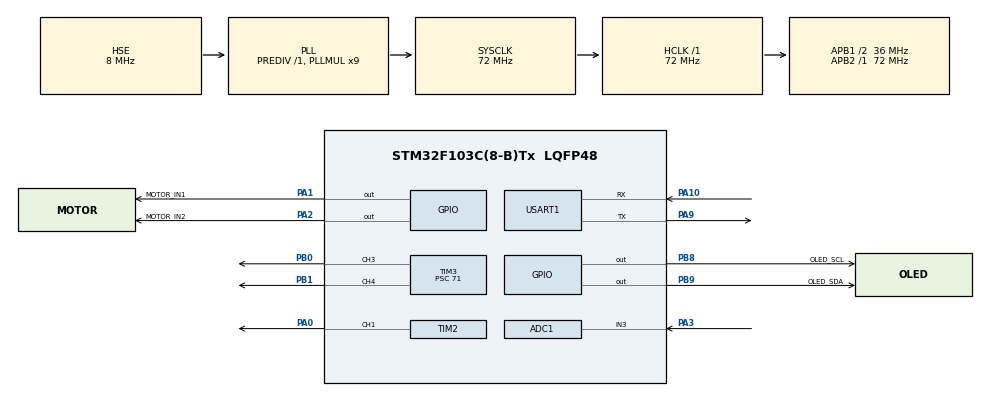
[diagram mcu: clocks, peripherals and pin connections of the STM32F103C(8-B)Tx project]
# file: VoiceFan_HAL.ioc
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ADC1.Channel-0\#ChannelRegularConversion=ADC_CHANNEL_3
ADC1.NbrOfConversionFlag=1
ADC1.Rank-0\#ChannelRegularConversion=1
ADC1.SamplingTime-0\#ChannelRegularConversion=ADC_SAMPLETIME_55CYCLES_5
ADC1.master=1
Mcu.Family=STM32F1
Mcu.Name=STM32F103C(8-B)Tx
Mcu.Package=LQFP48
NVIC.PriorityGroup=NVIC_PRIORITYGROUP_2
NVIC.TIM3_IRQn=true\:0\:0\:false\:false\:true\:true\:true\:true
NVIC.USART1_IRQn=true\:1\:1\:true\:false\:true\:true\:true\:true
PA0-WKUP.Signal=S_TIM2_CH1_ETR
PA1.GPIO_Label=MOTOR_IN1
PA1.GPIO_Speed=GPIO_SPEED_FREQ_HIGH
PA1.Signal=GPIO_Output
PA10.GPIO_PuPd=GPIO_PULLUP
PA10.Mode=Asynchronous
PA10.Signal=USART1_RX
PA13.Mode=Serial_Wire
PA13.Signal=SYS_JTMS-SWDIO
PA14.Mode=Serial_Wire
PA14.Signal=SYS_JTCK-SWCLK
PA2.GPIO_Label=MOTOR_IN2
PA2.GPIO_Speed=GPIO_SPEED_FREQ_HIGH
PA2.Signal=GPIO_Output
PA3.Signal=ADCx_IN3
PA9.Mode=Asynchronous
PA9.Signal=USART1_TX
PB0.Signal=S_TIM3_CH3
PB1.Signal=S_TIM3_CH4
PB8.GPIO_Label=OLED_SCL
PB8.GPIO_ModeDefaultOutputPP=GPIO_MODE_OUTPUT_OD
PB8.GPIO_PuPd=GPIO_NOPULL
PB8.GPIO_Speed=GPIO_SPEED_FREQ_HIGH
PB8.Signal=GPIO_Output
PB9.GPIO_Label=OLED_SDA
PB9.GPIO_ModeDefaultOutputPP=GPIO_MODE_OUTPUT_OD
PB9.GPIO_PuPd=GPIO_NOPULL
PB9.GPIO_Speed=GPIO_SPEED_FREQ_HIGH
PB9.Signal=GPIO_Output
PD0-OSC_IN.Mode=HSE-External-Oscillator
PD0-OSC_IN.Signal=RCC_OSC_IN
PD1-OSC_OUT.Mode=HSE-External-Oscillator
PD1-OSC_OUT.Signal=RCC_OSC_OUT
ProjectManager.HeapSize=0x200
ProjectManager.StackSize=0x400
ProjectManager.TargetToolchain=MDK-ARM V5.32
RCC.ADCPresc=RCC_ADCPCLK2_DIV6
RCC.AHBFreq_Value=72000000
RCC.APB1CLKDivider=RCC_HCLK_DIV2
RCC.APB1Freq_Value=36000000
RCC.APB1TimFreq_Value=72000000
RCC.APB2Freq_Value=72000000
RCC.APB2TimFreq_Value=72000000
RCC.HCLKFreq_Value=72000000
RCC.PLLMUL=RCC_PLL_MUL9
RCC.PLLSourceVirtual=RCC_PLLSOURCE_HSE
RCC.SYSCLKFreq_VALUE=72000000
RCC.SYSCLKSource=RCC_SYSCLKSOURCE_PLLCLK
RCC.USBFreq_Value=72000000
SH.ADCx_IN3.0=ADC1_IN3,IN3
SH.S_TIM2_CH1_ETR.0=TIM2_CH1,PWM Generation1 CH1
SH.S_TIM3_CH3.0=TIM3_CH3,PWM Generation3 CH3
SH.S_TIM3_CH4.0=TIM3_CH4,PWM Generation4 CH4
TIM2.AutoReloadPreload=TIM_AUTORELOAD_PRELOAD_ENABLE
TIM2.Channel-PWM\ Generation1\ CH1=TIM_CHANNEL_1
TIM2.Period=99
TIM2.Prescaler=35
TIM3.AutoReloadPreload=TIM_AUTORELOAD_PRELOAD_ENABLE
TIM3.Channel-PWM\ Generation3\ CH3=TIM_CHANNEL_3
TIM3.Channel-PWM\ Generation4\ CH4=TIM_CHANNEL_4
TIM3.Period=19999
TIM3.Prescaler=71
USART1.VirtualMode=VM_ASYNC
VP_TIM2_VS_ClockSourceINT.Mode=Internal
VP_TIM3_VS_ClockSourceINT.Mode=Internal
board=custom

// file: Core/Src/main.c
/* USER CODE BEGIN Header */
/**
  ******************************************************************************
  * @file           : main.c
  * @brief          : Main program body
  ******************************************************************************
  * @attention
  *
  * Copyright (c) 2026 STMicroelectronics.
  * All rights reserved.
  *
  * This software is licensed under terms that can be found in the LICENSE file
  * in the root directory of this software component.
  * If no LICENSE file comes with this software, it is provided AS-IS.
  *
  ******************************************************************************
  */
/* USER CODE END Header */
#include "main.h"
#include "adc.h"
#include "tim.h"
#include "usart.h"
#include "gpio.h"

/* USER CODE BEGIN Includes */
#include "BSP.h"
/* USER CODE END Includes */

void SystemClock_Config(void);

int main(void)
{

  /* MCU Configuration--------------------------------------------------------*/

  /* Reset of all peripherals, Initializes the Flash interface and the Systick. */
  HAL_Init();

  /* Configure the system clock */
  SystemClock_Config();

  /* Initialize all configured peripherals */
  MX_GPIO_Init();
  MX_ADC1_Init();
  MX_TIM2_Init();
  MX_TIM3_Init();
  MX_USART1_UART_Init();
  /* USER CODE BEGIN 2 */
	BSP_Init();
	OLED_ShowImage(0,0,128,64,Face_eyes);
	OLED_Update();
  /* USER CODE END 2 */

  /* Infinite loop */
  while (1)
  {

    /* USER CODE BEGIN 3 */
	  //AllLed=1;
	  //BreatheLed=1;
	  //Fan_Swing=1;
	  //Face_Mode=0;
	  //Fan_Speed=1;
	Face_Config();
	OperatingMode();
  }
  /* USER CODE END 3 */
}

void SystemClock_Config(void)
{
  RCC_OscInitTypeDef RCC_OscInitStruct = {0};
  RCC_ClkInitTypeDef RCC_ClkInitStruct = {0};
  RCC_PeriphCLKInitTypeDef PeriphClkInit = {0};

  /** Initializes the RCC Oscillators according to the specified parameters
  * in the RCC_OscInitTypeDef structure.
  */
  RCC_OscInitStruct.OscillatorType = RCC_OSCILLATORTYPE_HSE;
  RCC_OscInitStruct.HSEState = RCC_HSE_ON;
  RCC_OscInitStruct.HSEPredivValue = RCC_HSE_PREDIV_DIV1;
  RCC_OscInitStruct.HSIState = RCC_HSI_ON;
  RCC_OscInitStruct.PLL.PLLState = RCC_PLL_ON;
  RCC_OscInitStruct.PLL.PLLSource = RCC_PLLSOURCE_HSE;
  RCC_OscInitStruct.PLL.PLLMUL = RCC_PLL_MUL9;
  if (HAL_RCC_OscConfig(&RCC_OscInitStruct) != HAL_OK)
  {
    Error_Handler();
  }

  /** Initializes the CPU, AHB and APB buses clocks
  */
  RCC_ClkInitStruct.ClockType = RCC_CLOCKTYPE_HCLK|RCC_CLOCKTYPE_SYSCLK
                              |RCC_CLOCKTYPE_PCLK1|RCC_CLOCKTYPE_PCLK2;
  RCC_ClkInitStruct.SYSCLKSource = RCC_SYSCLKSOURCE_PLLCLK;
  RCC_ClkInitStruct.AHBCLKDivider = RCC_SYSCLK_DIV1;
  RCC_ClkInitStruct.APB1CLKDivider = RCC_HCLK_DIV2;
  RCC_ClkInitStruct.APB2CLKDivider = RCC_HCLK_DIV1;

  if (HAL_RCC_ClockConfig(&RCC_ClkInitStruct, FLASH_LATENCY_2) != HAL_OK)
  {
    Error_Handler();
  }
  PeriphClkInit.PeriphClockSelection = RCC_PERIPHCLK_ADC;
  PeriphClkInit.AdcClockSelection = RCC_ADCPCLK2_DIV6;
  if (HAL_RCCEx_PeriphCLKConfig(&PeriphClkInit) != HAL_OK)
  {
    Error_Handler();
  }
}

/* USER CODE BEGIN 4 */
/**
  * @brief  TIM3 周期溢出回调（每 20ms 触发一次）
  */
void HAL_TIM_PeriodElapsedCallback(TIM_HandleTypeDef *htim)
{
    if (htim->Instance == TIM3)
    {
        GetCur_Power();      /* 电量检测 */
        Servo_Update();      /* 舵机更新 */
        LED_Breathing();     /* 呼吸灯 */
    }
}
/* USER CODE END 4 */

void Error_Handler(void)
{
  __disable_irq();
  while (1)
  {
  }
}
